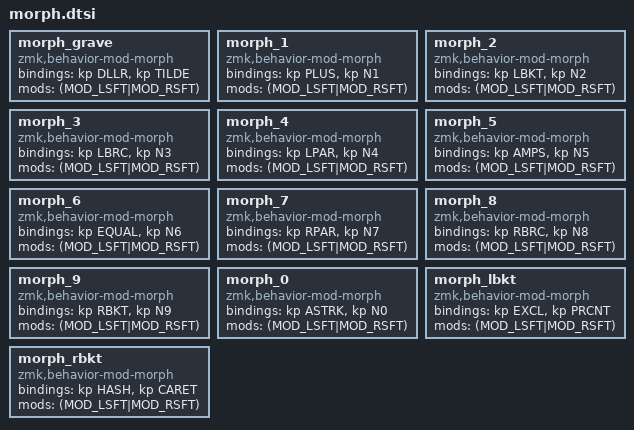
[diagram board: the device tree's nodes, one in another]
// Dvorak number row mod-morphs - correct Dvorak layout
// Base: $ + [ { ( & = ) } ] * ! # 
// Shift: ~ 1 2 3 4 5 6 7 8 9 0 % ^

morph_grave: morph_grave {
    compatible = "zmk,behavior-mod-morph";
    #binding-cells = <0>;
    bindings = <&kp DLLR>, <&kp TILDE>;
    mods = <(MOD_LSFT|MOD_RSFT)>;
};

morph_1: morph_1 {
    compatible = "zmk,behavior-mod-morph";
    #binding-cells = <0>;
    bindings = <&kp PLUS>, <&kp N1>;
    mods = <(MOD_LSFT|MOD_RSFT)>;
};

morph_2: morph_2 {
    compatible = "zmk,behavior-mod-morph";
    #binding-cells = <0>;
    bindings = <&kp LBKT>, <&kp N2>;
    mods = <(MOD_LSFT|MOD_RSFT)>;
};

morph_3: morph_3 {
    compatible = "zmk,behavior-mod-morph";
    #binding-cells = <0>;
    bindings = <&kp LBRC>, <&kp N3>;
    mods = <(MOD_LSFT|MOD_RSFT)>;
};

morph_4: morph_4 {
    compatible = "zmk,behavior-mod-morph";
    #binding-cells = <0>;
    bindings = <&kp LPAR>, <&kp N4>;
    mods = <(MOD_LSFT|MOD_RSFT)>;
};

morph_5: morph_5 {
    compatible = "zmk,behavior-mod-morph";
    #binding-cells = <0>;
    bindings = <&kp AMPS>, <&kp N5>;
    mods = <(MOD_LSFT|MOD_RSFT)>;
};

morph_6: morph_6 {
    compatible = "zmk,behavior-mod-morph";
    #binding-cells = <0>;
    bindings = <&kp EQUAL>, <&kp N6>;
    mods = <(MOD_LSFT|MOD_RSFT)>;
};

morph_7: morph_7 {
    compatible = "zmk,behavior-mod-morph";
    #binding-cells = <0>;
    bindings = <&kp RPAR>, <&kp N7>;
    mods = <(MOD_LSFT|MOD_RSFT)>;
};

morph_8: morph_8 {
    compatible = "zmk,behavior-mod-morph";
    #binding-cells = <0>;
    bindings = <&kp RBRC>, <&kp N8>;
    mods = <(MOD_LSFT|MOD_RSFT)>;
};

morph_9: morph_9 {
    compatible = "zmk,behavior-mod-morph";
    #binding-cells = <0>;
    bindings = <&kp RBKT>, <&kp N9>;
    mods = <(MOD_LSFT|MOD_RSFT)>;
};

morph_0: morph_0 {
    compatible = "zmk,behavior-mod-morph";
    #binding-cells = <0>;
    bindings = <&kp ASTRK>, <&kp N0>;
    mods = <(MOD_LSFT|MOD_RSFT)>;
};

morph_lbkt: morph_lbkt {
    compatible = "zmk,behavior-mod-morph";
    #binding-cells = <0>;
    bindings = <&kp EXCL>, <&kp PRCNT>;
    mods = <(MOD_LSFT|MOD_RSFT)>;
};

morph_rbkt: morph_rbkt {
    compatible = "zmk,behavior-mod-morph";
    #binding-cells = <0>;
    bindings = <&kp HASH>, <&kp CARET>;
    mods = <(MOD_LSFT|MOD_RSFT)>;
};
